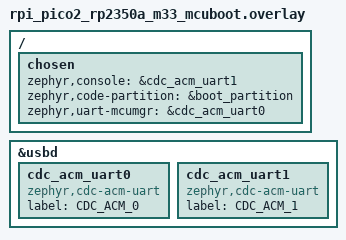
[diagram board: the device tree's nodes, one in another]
/ { 

	chosen {
		zephyr,console = &cdc_acm_uart1;
		//zephyr,shell-uart = &cdc_acm_uart1;
		zephyr,code-partition = &boot_partition;
		zephyr,uart-mcumgr = &cdc_acm_uart0;
	};
};

zephyr_udc0: &usbd {
	//compatible = "raspberrypi,rp-usbd";
	status = "okay";
	cdc_acm_uart0: cdc_acm_uart0 {
		status = "okay";
		compatible = "zephyr,cdc-acm-uart";
		label = "CDC_ACM_0";
	};
	cdc_acm_uart1: cdc_acm_uart1 {
		status = "okay";
		compatible = "zephyr,cdc-acm-uart";
		label = "CDC_ACM_1";
	};
};


